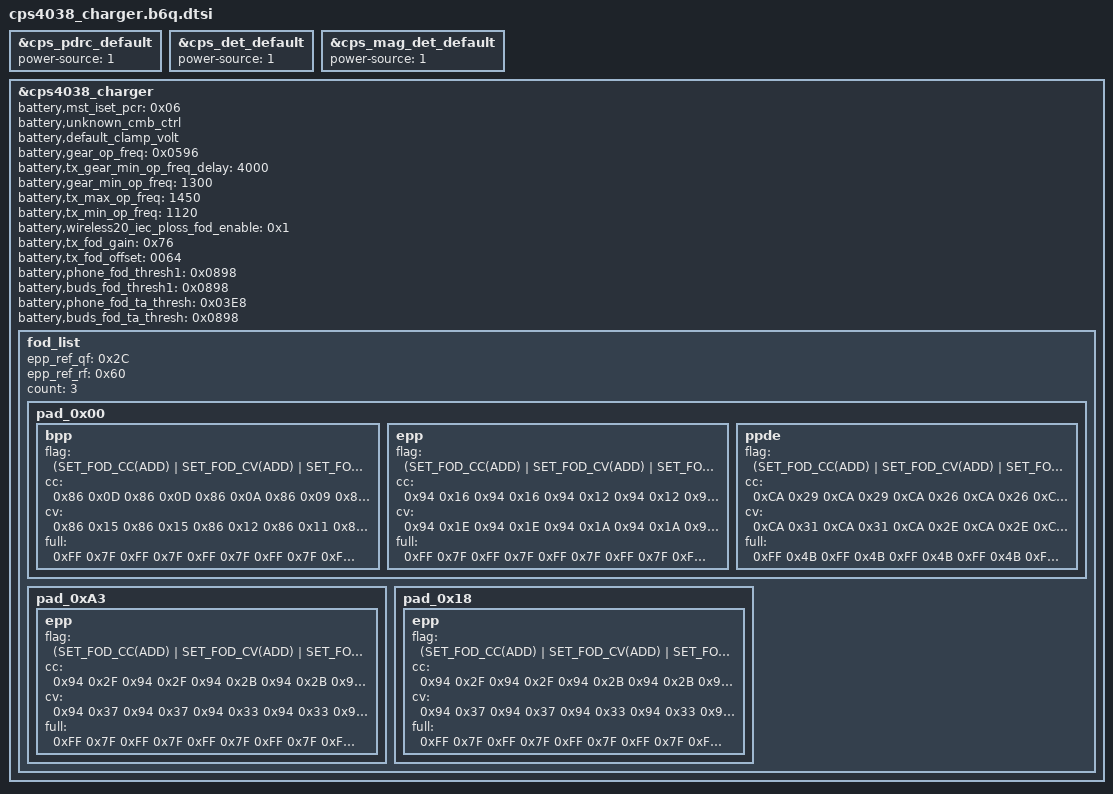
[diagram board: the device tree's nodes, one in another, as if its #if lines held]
#include <dt-bindings/battery/sec-battery.h>

&cps_pdrc_default {
	power-source = <1>; /* need to set default MV gpio to LV */
};

&cps_det_default {
	power-source = <1>; /* need to set default MV gpio to LV */
};

#if ${feature_use_gpio_mag_det}(get)
&cps_mag_det_default {
	power-source = <1>; /* need to set default MV gpio to LV */
};
#endif

&cps4038_charger {
	battery,mst_iset_pcr = <0x06>;  //2.8A
	battery,unknown_cmb_ctrl;
	battery,default_clamp_volt;
	battery,gear_op_freq = <0x0596>; /* 143kHZ */
	battery,tx_gear_min_op_freq_delay = <4000>;
	battery,gear_min_op_freq = <1300>;

	battery,tx_max_op_freq = <1450>;
	battery,tx_min_op_freq = <1120>;
	battery,wireless20_iec_ploss_fod_enable = <0x1>;
	battery,tx_fod_gain = <0x76>;
	battery,tx_fod_offset = <0064>;
	battery,phone_fod_thresh1 = <0x0898>;
	battery,buds_fod_thresh1 = <0x0898>;
	battery,phone_fod_ta_thresh = <0x03E8>;
	battery,buds_fod_ta_thresh = <0x0898>;

	fod_list {
		epp_ref_qf = <0x2C>;
		epp_ref_rf = <0x60>;

		count = <3>;

		pad_0x00 { /* DEFAULT */
			bpp { /* DEFAULT OP MODE */
				flag = <(SET_FOD_CC(ADD) | SET_FOD_CV(ADD) | SET_FOD_FULL(ADD))>;
				cc = <0x86 0x0D 0x86 0x0D 0x86 0x0A 0x86 0x09 0x86 0x09 0x86 0x09 0x86 0x0A 0x86 0x0A 0x86 0x0A 0x86 0x0A>;
				cv = <0x86 0x15 0x86 0x15 0x86 0x12 0x86 0x11 0x86 0x11 0x86 0x11 0x86 0x12 0x86 0x12 0x86 0x12 0x86 0x12>;
				full = <0xFF 0x7F 0xFF 0x7F 0xFF 0x7F 0xFF 0x7F 0xFF 0x7F 0xFF 0x7F 0xFF 0x7F 0xFF 0x7F 0xFF 0x7F 0xFF 0x7F>;
			};

			epp {
				flag = <(SET_FOD_CC(ADD) | SET_FOD_CV(ADD) | SET_FOD_FULL(ADD))>;
				cc = <0x94 0x16 0x94 0x16 0x94 0x12 0x94 0x12 0x94 0x15 0x94 0x16 0x94 0x18 0x94 0x18 0x94 0x18 0x0C 0x01>;
				cv = <0x94 0x1E 0x94 0x1E 0x94 0x1A 0x94 0x1A 0x94 0x1D 0x94 0x1E 0x94 0x20 0x94 0x20 0x94 0x20 0x0C 0x01>;
				full = <0xFF 0x7F 0xFF 0x7F 0xFF 0x7F 0xFF 0x7F 0xFF 0x7F 0xFF 0x7F 0xFF 0x7F 0xFF 0x7F 0xFF 0x7F 0xFF 0x7F>;
			};

			ppde {
				flag = <(SET_FOD_CC(ADD) | SET_FOD_CV(ADD) | SET_FOD_FULL(ADD))>;
				cc = <0xCA 0x29 0xCA 0x29 0xCA 0x26 0xCA 0x26 0xCA 0x26 0xCA 0x26 0xCA 0x26 0xCA 0x26 0xCA 0x26 0xCA 0x26>;
				cv = <0xCA 0x31 0xCA 0x31 0xCA 0x2E 0xCA 0x2E 0xCA 0x2E 0xCA 0x2E 0xCA 0x2E 0xCA 0x2E 0xCA 0x2E 0xCA 0x2E>;
				full = <0xFF 0x4B 0xFF 0x4B 0xFF 0x4B 0xFF 0x4B 0xFF 0x4B 0xFF 0x4B 0xFF 0x4B 0xFF 0x4B 0xFF 0x4B 0xFF 0x4B>;
			};
		};

		pad_0xA3 { /* p2400 */
			epp {
				flag = <(SET_FOD_CC(ADD) | SET_FOD_CV(ADD) | SET_FOD_FULL(ADD))>;
				cc = <0x94 0x2F 0x94 0x2F 0x94 0x2B 0x94 0x2B 0x94 0x2E 0x94 0x2F 0x94 0x31 0x94 0x31 0x94 0x31 0x0C 0x01>;
				cv = <0x94 0x37 0x94 0x37 0x94 0x33 0x94 0x33 0x94 0x36 0x94 0x37 0x94 0x39 0x94 0x39 0x94 0x39 0x0C 0x01>;
				full = <0xFF 0x7F 0xFF 0x7F 0xFF 0x7F 0xFF 0x7F 0xFF 0x7F 0xFF 0x7F 0xFF 0x7F 0xFF 0x7F 0xFF 0x7F 0xFF 0x7F>;
			};
		};
		
		pad_0x18 { /* p2400 */
			epp {
				flag = <(SET_FOD_CC(ADD) | SET_FOD_CV(ADD) | SET_FOD_FULL(ADD))>;
				cc = <0x94 0x2F 0x94 0x2F 0x94 0x2B 0x94 0x2B 0x94 0x2E 0x94 0x2F 0x94 0x31 0x94 0x31 0x94 0x31 0x0C 0x01>;
				cv = <0x94 0x37 0x94 0x37 0x94 0x33 0x94 0x33 0x94 0x36 0x94 0x37 0x94 0x39 0x94 0x39 0x94 0x39 0x0C 0x01>;
				full = <0xFF 0x7F 0xFF 0x7F 0xFF 0x7F 0xFF 0x7F 0xFF 0x7F 0xFF 0x7F 0xFF 0x7F 0xFF 0x7F 0xFF 0x7F 0xFF 0x7F>;
			};
		};
	};
};
